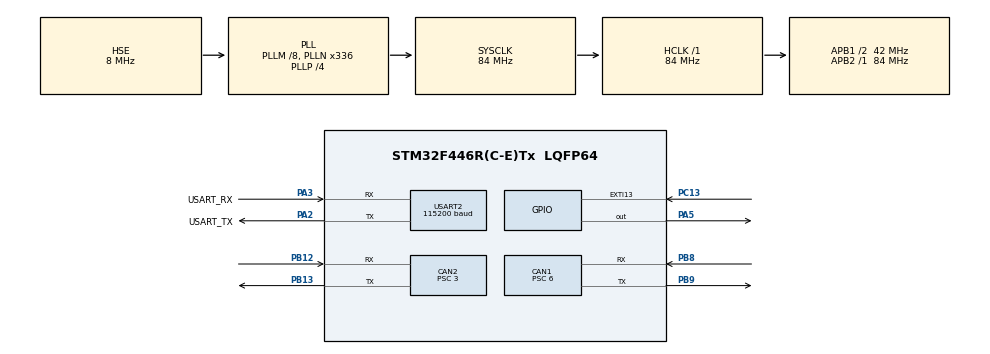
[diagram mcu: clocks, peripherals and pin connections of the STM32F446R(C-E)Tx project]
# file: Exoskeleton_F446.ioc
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CAN1.BS1=CAN_BS1_11TQ
CAN1.BS2=CAN_BS2_2TQ
CAN1.CalculateBaudRate=500000
CAN1.CalculateTimeBit=2000
CAN1.CalculateTimeQuantum=142.85714285714286
CAN1.Prescaler=6
CAN1.RFLM=ENABLE
CAN2.BS1=CAN_BS1_11TQ
CAN2.BS2=CAN_BS2_2TQ
CAN2.CalculateBaudRate=1000000
CAN2.CalculateTimeBit=1000
CAN2.CalculateTimeQuantum=71.42857142857143
CAN2.Prescaler=3
CAN2.RFLM=ENABLE
Dma.Request0=USART2_RX
Dma.Request1=USART2_TX
Dma.USART2_RX.0.Direction=DMA_PERIPH_TO_MEMORY
Dma.USART2_RX.0.FIFOMode=DMA_FIFOMODE_DISABLE
Dma.USART2_RX.0.Instance=DMA1_Stream5
Dma.USART2_RX.0.MemDataAlignment=DMA_MDATAALIGN_BYTE
Dma.USART2_RX.0.MemInc=DMA_MINC_ENABLE
Dma.USART2_RX.0.Mode=DMA_CIRCULAR
Dma.USART2_RX.0.PeriphDataAlignment=DMA_PDATAALIGN_BYTE
Dma.USART2_RX.0.PeriphInc=DMA_PINC_DISABLE
Dma.USART2_RX.0.Priority=DMA_PRIORITY_HIGH
Dma.USART2_TX.1.Direction=DMA_MEMORY_TO_PERIPH
Dma.USART2_TX.1.FIFOMode=DMA_FIFOMODE_DISABLE
Dma.USART2_TX.1.Instance=DMA1_Stream6
Dma.USART2_TX.1.MemDataAlignment=DMA_MDATAALIGN_BYTE
Dma.USART2_TX.1.MemInc=DMA_MINC_ENABLE
Dma.USART2_TX.1.Mode=DMA_NORMAL
Dma.USART2_TX.1.PeriphDataAlignment=DMA_PDATAALIGN_BYTE
Dma.USART2_TX.1.PeriphInc=DMA_PINC_DISABLE
Dma.USART2_TX.1.Priority=DMA_PRIORITY_LOW
Mcu.Family=STM32F4
Mcu.Name=STM32F446R(C-E)Tx
Mcu.Package=LQFP64
NUCLEO-F446RE.BUTTON=1
NUCLEO-F446RE.LD1=true
NVIC.CAN1_RX0_IRQn=true\:5\:0\:false\:false\:true\:true\:true\:true
NVIC.CAN1_SCE_IRQn=true\:5\:0\:false\:false\:true\:true\:true\:true
NVIC.CAN2_RX1_IRQn=true\:5\:0\:false\:false\:true\:true\:true\:true
NVIC.CAN2_SCE_IRQn=true\:5\:0\:false\:false\:true\:true\:true\:true
NVIC.DMA1_Stream5_IRQn=true\:5\:0\:false\:false\:true\:true\:true\:true
NVIC.DMA1_Stream6_IRQn=true\:5\:0\:false\:false\:true\:true\:true\:true
NVIC.EXTI15_10_IRQn=true\:10\:0\:false\:false\:true\:false\:true\:true
NVIC.PriorityGroup=NVIC_PRIORITYGROUP_4
NVIC.USART2_IRQn=true\:5\:0\:false\:false\:true\:true\:true\:true
PA13.GPIO_Label=TMS
PA13.Signal=SYS_JTMS-SWDIO
PA14.GPIO_Label=TCK
PA14.Signal=SYS_JTCK-SWCLK
PA2.GPIO_Label=USART_TX
PA2.Mode=Asynchronous
PA2.Signal=USART2_TX
PA3.GPIO_Label=USART_RX
PA3.Mode=Asynchronous
PA3.Signal=USART2_RX
PA5.Signal=GPIO_Output
PB12.Mode=CAN_Activate
PB12.Signal=CAN2_RX
PB13.Mode=CAN_Activate
PB13.Signal=CAN2_TX
PB3.GPIO_Label=SWO
PB3.Signal=SYS_JTDO-SWO
PB8.Mode=CAN_Activate
PB8.Signal=CAN1_RX
PB9.Mode=CAN_Activate
PB9.Signal=CAN1_TX
PC13.Signal=GPXTI13
PC14-OSC32_IN.Signal=RCC_OSC32_IN
PC15-OSC32_OUT.Signal=RCC_OSC32_OUT
PH0-OSC_IN.Signal=RCC_OSC_IN
PH1-OSC_OUT.Signal=RCC_OSC_OUT
ProjectManager.HeapSize=0x200
ProjectManager.StackSize=0x400
ProjectManager.TargetToolchain=CMake
RCC.AHBFreq_Value=84000000
RCC.APB1CLKDivider=RCC_HCLK_DIV2
RCC.APB1Freq_Value=42000000
RCC.APB1TimFreq_Value=84000000
RCC.APB2Freq_Value=84000000
RCC.APB2TimFreq_Value=84000000
RCC.CortexFreq_Value=84000000
RCC.FLatency-AdvancedSettings=FLASH_LATENCY_2
RCC.HCLKFreq_Value=84000000
RCC.HSE_VALUE=8000000
RCC.HSI_VALUE=16000000
RCC.LSE_VALUE=32768
RCC.PLLN=336
RCC.PLLP=RCC_PLLP_DIV4
RCC.SYSCLKFreq_VALUE=84000000
RCC.SYSCLKSource=RCC_SYSCLKSOURCE_PLLCLK
RCC.USBFreq_Value=168000000
RCC.VCOOutputFreq_Value=336000000
USART2.BaudRate=115200
USART2.VirtualMode=VM_ASYNC
VP_NUCLEO-F446RE_VS_BSP_COMMON.Mode=COMMON
board=NUCLEO-F446RE
PH0-OSC_IN.Mode=HSE-External-Clock-Source
PH1-OSC_OUT.Mode=HSE-External-Clock-Source
RCC.PLLM=8
RCC.PLLSourceVirtual=RCC_PLLSOURCE_HSE

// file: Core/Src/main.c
/* USER CODE BEGIN Header */
/**
  ******************************************************************************
  * @file           : main.c
  * @brief          : Main program body
  ******************************************************************************
  * @attention
  *
  * Copyright (c) 2026 STMicroelectronics.
  * All rights reserved.
  *
  * This software is licensed under terms that can be found in the LICENSE file
  * in the root directory of this software component.
  * If no LICENSE file comes with this software, it is provided AS-IS.
  *
  ******************************************************************************
  */
/* USER CODE END Header */
#include "main.h"

/* USER CODE BEGIN Includes */
#include "app_main.h"
#include "board_runtime.h"
#include "board_can.h"

/* USER CODE END Includes */

CAN_HandleTypeDef hcan1;
CAN_HandleTypeDef hcan2;

UART_HandleTypeDef huart2;
DMA_HandleTypeDef hdma_usart2_rx;
DMA_HandleTypeDef hdma_usart2_tx;

void SystemClock_Config(void);
static void MX_GPIO_Init(void);
static void MX_DMA_Init(void);
static void MX_USART2_UART_Init(void);
static void MX_CAN1_Init(void);
static void MX_CAN2_Init(void);

int main(void)
{

  /* MCU Configuration--------------------------------------------------------*/

  /* Reset of all peripherals, Initializes the Flash interface and the Systick. */
  HAL_Init();

  /* Configure the system clock */
  SystemClock_Config();

  /* Initialize all configured peripherals */
  MX_GPIO_Init();
  MX_DMA_Init();
  MX_USART2_UART_Init();
  MX_CAN1_Init();
  MX_CAN2_Init();

  /* Initialize leds */
  BSP_LED_Init(LED2);

  /* Initialize USER push-button, will be used to trigger an interrupt each time it's pressed.*/
  BSP_PB_Init(BUTTON_USER, BUTTON_MODE_EXTI);

  /* Infinite loop */
  /* USER CODE BEGIN WHILE */
  if (!BoardRuntime_FinalizeInterrupts()) {
    BoardRuntime_FatalBlink();
  }
  App_Init();
  while (1)
  {

    /* USER CODE END WHILE */

    /* USER CODE BEGIN 3 */
    App_Poll();
  }
  /* USER CODE END 3 */
}

void SystemClock_Config(void)
{
  RCC_OscInitTypeDef RCC_OscInitStruct = {0};
  RCC_ClkInitTypeDef RCC_ClkInitStruct = {0};

  /** Configure the main internal regulator output voltage
  */
  __HAL_RCC_PWR_CLK_ENABLE();
  __HAL_PWR_VOLTAGESCALING_CONFIG(PWR_REGULATOR_VOLTAGE_SCALE3);

  /** Initializes the RCC Oscillators according to the specified parameters
  * in the RCC_OscInitTypeDef structure.
  */
  RCC_OscInitStruct.OscillatorType = RCC_OSCILLATORTYPE_HSE;
  RCC_OscInitStruct.HSEState = RCC_HSE_BYPASS;
  RCC_OscInitStruct.PLL.PLLState = RCC_PLL_ON;
  RCC_OscInitStruct.PLL.PLLSource = RCC_PLLSOURCE_HSE;
  RCC_OscInitStruct.PLL.PLLM = 8;
  RCC_OscInitStruct.PLL.PLLN = 336;
  RCC_OscInitStruct.PLL.PLLP = RCC_PLLP_DIV4;
  RCC_OscInitStruct.PLL.PLLQ = 2;
  RCC_OscInitStruct.PLL.PLLR = 2;
  if (HAL_RCC_OscConfig(&RCC_OscInitStruct) != HAL_OK)
  {
    Error_Handler();
  }

  /** Initializes the CPU, AHB and APB buses clocks
  */
  RCC_ClkInitStruct.ClockType = RCC_CLOCKTYPE_HCLK|RCC_CLOCKTYPE_SYSCLK
                              |RCC_CLOCKTYPE_PCLK1|RCC_CLOCKTYPE_PCLK2;
  RCC_ClkInitStruct.SYSCLKSource = RCC_SYSCLKSOURCE_PLLCLK;
  RCC_ClkInitStruct.AHBCLKDivider = RCC_SYSCLK_DIV1;
  RCC_ClkInitStruct.APB1CLKDivider = RCC_HCLK_DIV2;
  RCC_ClkInitStruct.APB2CLKDivider = RCC_HCLK_DIV1;

  if (HAL_RCC_ClockConfig(&RCC_ClkInitStruct, FLASH_LATENCY_2) != HAL_OK)
  {
    Error_Handler();
  }
}

static void MX_CAN1_Init(void)
{

  /* USER CODE BEGIN CAN1_Init 0 */
  BoardCan_InitBegin(BOARD_CAN_SHOULDER);
  /* USER CODE END CAN1_Init 0 */

  hcan1.Instance = CAN1;
  hcan1.Init.Prescaler = 6;
  hcan1.Init.Mode = CAN_MODE_NORMAL;
  hcan1.Init.SyncJumpWidth = CAN_SJW_1TQ;
  hcan1.Init.TimeSeg1 = CAN_BS1_11TQ;
  hcan1.Init.TimeSeg2 = CAN_BS2_2TQ;
  hcan1.Init.TimeTriggeredMode = DISABLE;
  hcan1.Init.AutoBusOff = DISABLE;
  hcan1.Init.AutoWakeUp = DISABLE;
  hcan1.Init.AutoRetransmission = DISABLE;
  hcan1.Init.ReceiveFifoLocked = ENABLE;
  hcan1.Init.TransmitFifoPriority = DISABLE;
  if (HAL_CAN_Init(&hcan1) != HAL_OK)
  {
    Error_Handler();
  }
  /* USER CODE BEGIN CAN1_Init 2 */
  BoardCan_InitEnd();
  /* USER CODE END CAN1_Init 2 */

}

static void MX_CAN2_Init(void)
{

  /* USER CODE BEGIN CAN2_Init 0 */
  BoardCan_InitBegin(BOARD_CAN_ELBOW);
  /* USER CODE END CAN2_Init 0 */

  hcan2.Instance = CAN2;
  hcan2.Init.Prescaler = 3;
  hcan2.Init.Mode = CAN_MODE_NORMAL;
  hcan2.Init.SyncJumpWidth = CAN_SJW_1TQ;
  hcan2.Init.TimeSeg1 = CAN_BS1_11TQ;
  hcan2.Init.TimeSeg2 = CAN_BS2_2TQ;
  hcan2.Init.TimeTriggeredMode = DISABLE;
  hcan2.Init.AutoBusOff = DISABLE;
  hcan2.Init.AutoWakeUp = DISABLE;
  hcan2.Init.AutoRetransmission = DISABLE;
  hcan2.Init.ReceiveFifoLocked = ENABLE;
  hcan2.Init.TransmitFifoPriority = DISABLE;
  if (HAL_CAN_Init(&hcan2) != HAL_OK)
  {
    Error_Handler();
  }
  /* USER CODE BEGIN CAN2_Init 2 */
  BoardCan_InitEnd();
  /* USER CODE END CAN2_Init 2 */

}

static void MX_USART2_UART_Init(void)
{

  huart2.Instance = USART2;
  huart2.Init.BaudRate = 115200;
  huart2.Init.WordLength = UART_WORDLENGTH_8B;
  huart2.Init.StopBits = UART_STOPBITS_1;
  huart2.Init.Parity = UART_PARITY_NONE;
  huart2.Init.Mode = UART_MODE_TX_RX;
  huart2.Init.HwFlowCtl = UART_HWCONTROL_NONE;
  huart2.Init.OverSampling = UART_OVERSAMPLING_16;
  if (HAL_UART_Init(&huart2) != HAL_OK)
  {
    Error_Handler();
  }

}

static void MX_DMA_Init(void)
{

  /* DMA controller clock enable */
  __HAL_RCC_DMA1_CLK_ENABLE();

  /* DMA interrupt init */
  /* DMA1_Stream5_IRQn interrupt configuration */
  HAL_NVIC_SetPriority(DMA1_Stream5_IRQn, 5, 0);
  HAL_NVIC_EnableIRQ(DMA1_Stream5_IRQn);
  /* DMA1_Stream6_IRQn interrupt configuration */
  HAL_NVIC_SetPriority(DMA1_Stream6_IRQn, 5, 0);
  HAL_NVIC_EnableIRQ(DMA1_Stream6_IRQn);

}

static void MX_GPIO_Init(void)
{

  /* GPIO Ports Clock Enable */
  __HAL_RCC_GPIOC_CLK_ENABLE();
  __HAL_RCC_GPIOH_CLK_ENABLE();
  __HAL_RCC_GPIOA_CLK_ENABLE();
  __HAL_RCC_GPIOB_CLK_ENABLE();

}

void Error_Handler(void)
{
  /* USER CODE BEGIN Error_Handler_Debug */
  /* CAN init errors are observable over UART; other fatal errors still halt. */
  if (BoardCan_HandleInitFailure()) { return; }
  /* User can add his own implementation to report the HAL error return state */
  __disable_irq();
  while (1)
  {
  }
  /* USER CODE END Error_Handler_Debug */
}
